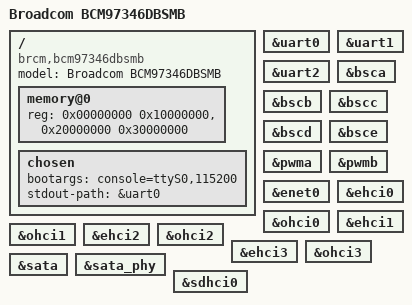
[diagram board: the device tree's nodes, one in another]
/dts-v1/;

/include/ "bcm7346.dtsi"

/ {
	compatible = "brcm,bcm97346dbsmb", "brcm,bcm7346";
	model = "Broadcom BCM97346DBSMB";

	memory@0 {
		device_type = "memory";
		reg = <0x00000000 0x10000000>, <0x20000000 0x30000000>;
	};

	chosen {
		bootargs = "console=ttyS0,115200";
		stdout-path = &uart0;
	};
};

&uart0 {
	status = "okay";
};

&uart1 {
	status = "okay";
};

&uart2 {
	status = "okay";
};

&bsca {
	status = "okay";
};

&bscb {
	status = "okay";
};

&bscc {
	status = "okay";
};

&bscd {
	status = "okay";
};

&bsce {
	status = "okay";
};

&pwma {
	status = "okay";
};

&pwmb {
	status = "okay";
};

&enet0 {
	status = "okay";
};

&ehci0 {
	status = "okay";
};

&ohci0 {
	status = "okay";
};

&ehci1 {
	status = "okay";
};

&ohci1 {
	status = "okay";
};

&ehci2 {
	status = "okay";
};

&ohci2 {
	status = "okay";
};

&ehci3 {
	status = "okay";
};

&ohci3 {
	status = "okay";
};

&sata {
	status = "okay";
};

&sata_phy {
	status = "okay";
};

&sdhci0 {
	status = "okay";
};
